# AE302F80F5582LE_CM55_HP_View register map
Vendor: Alif Semiconductor; Series: E3; File version: 1.0
CPU: CM55 r1p0, selectable endian, MPU, FPU, double-precision FPU, DSP, VTOR, 8 interrupt priority bits, 1 SAU regions
Registers are 32-bit, read-write, reset 0x0 unless marked. A register's access mark holds for its fields unless they carry their own. Offsets are from the block's base; [hi:lo] are bit positions; {n}, {i} and the like mark numbered series.

## CANFD0_CNT
Base 0x49037000
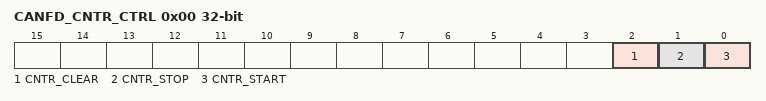
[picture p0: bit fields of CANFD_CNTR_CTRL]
0x00 CANFD_CNTR_CTRL wo — CANFD Counter Control Register
  [2] CNTR_CLEAR — Clear the CANFD counter.
  [1] CNTR_STOP — Stop the CANFD counter.
  [0] CNTR_START — Start the CANFD counter.
0x04 CANFD_CNTR_LOW — CANFD Counter Low Register
  [31:0] CNTR_LO — CANFD counter bits [31:0].
0x08 CANFD_CNTR_HIGH — CANFD Counter High Register
  [31:0] CNTR_HI — CANFD counter bits [63:32].

## AES0
Base 0x83001000
Same registers: AES1 0x83003000
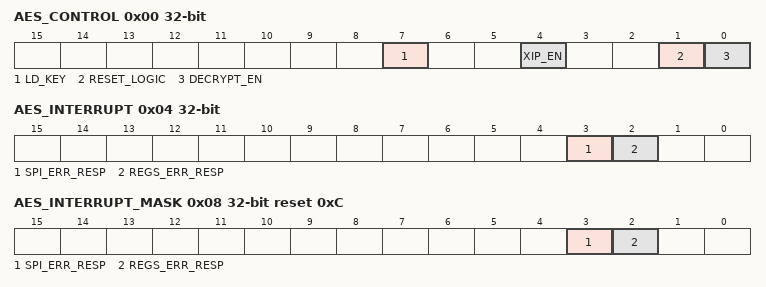
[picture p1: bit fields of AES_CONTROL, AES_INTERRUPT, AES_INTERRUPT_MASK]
0x00 AES_CONTROL
  [7] LD_KEY — Write 1 once the new key has been written by the Secure Enclave, so the key can be pre-processed by the AES engine. Read returns 0x0.
  [4] XIP_EN — When this bit is set, the OSPI can be used in XIP mode directly, with or without intervention from the decryption logic.
  [1] RESET_LOGIC — Reset the AES engine.
  [0] DECRYPT_EN — Decryption Enabled When set, this bit causes host read accesses to use the decryption logic rather than go directly to the OSPI module. Note that the OSPI module must be programmed to work in XIP mode prior to setting this bit.
0x04 AES_INTERRUPT — AES Interrupt Control Register
  [3] SPI_ERR_RESP — SPI Error Response interrupt enabling. Set when an error response is received from the OSPI through the AHB bus. Write 1 to clear bit.
    0=SPI Error Response interrupt is disabled; 1=SPI Error Response interrupt is enabled
  [2] REGS_ERR_RESP — Register Error Response interrupt enabling. Set when there is an access to an invalid AES register. Write 1 to clear bit.
    0=Register Error Response interrupt is disabled; 1=Register Error Response interrupt is enabled
0x08 AES_INTERRUPT_MASK reset 0xC
  [3] SPI_ERR_RESP — Mask for the SPI Error Response interrupt.
    0=SPI Error Response interrupt is not masked; 1=SPI Error Response interrupt is masked
  [2] REGS_ERR_RESP — Mask for the Register Error Response interrupt.
    0=Register Error Response interrupt is not masked; 1=Register Error Response interrupt is masked
0x20 AES_RXDS_DELAY — OSPI RXDS Delay Register
  [4:0] RXDS_DELAY — A delay added to the OSPI read data strobe (RXDS) input line in 0.5-ns steps. The maximum allowed value to program is 16. Note: The delay should be set to overcome the internal delay of OSPI input data lines (RXD) compared to the RXDS line. The objective is to ensure that the RXDS line is delayed by 1/4 OSPI clock cycle with respect to the leading edge of the valid RXD data lines. Equation to determine RXDS delay value: RXDS delay (ns) = RXD_delay (ns) + 0.25 x 1/FOSPI_SCLK For example, for internal RXD delay of 1.2 ns and 100 MHz OSPI clock, the RXDS delay = 1.2 ns + 0.25 x 1/100 MHz = 1.2 ns + 2.5 ns = 3.7 ns. The RXDS_DELAY code should be programmed to 0x8. This value may need to be calibrated for each specific application and may also depend on the pin multiplexing options selected for the OSPI data bus signals. For information on OSPI timing data, refer to Section OSPI Timing Characteristics of the device series-specific Datasheet.
    0=No delay; 1=0.5 ns delay; 2=2 x 0.5 ns delay; 15=15 x 0.5 ns delay; 16=16 x 0.5 ns delay

## M55HP_NVIC_S
Base 0xE000E100
Same registers: M55HP_NVIC_NS 0xE002E100
{0x0+4i} NVIC_ISER[{i}] (i=0..14) — Interrupt Set-Enable Register (n)
  [31:0] SETENA — Allows to enable an interrupt or read the status. For each bit: Read 0x0: Interrupt is disabled Read 0x1: Interrupt is enabled Write 0x0: No effect Write 0x1: Enable interrupt
{0x80+4i} NVIC_ICER[{i}] (i=0..14) — Interrupt Clear-Enable Register (n)
  [31:0] CLRENA — Allows to disable an interrupt or read the status. For each bit: Read 0x0: Interrupt is disabled Read 0x1: Interrupt is enabled Write 0x0: No effect Write 0x1: Disable interrupt
{0x100+4i} NVIC_ISPR[{i}] (i=0..14) — Interrupt Set-Pending Register (n)
  [31:0] SETPEND — Allows to set an interrupt to pending state or read the status. For each bit: Read 0x0: Interrupt is not pending Read 0x1: Interrupt is pending Write 0x0: No effect Write 0x1: Set interrupt to pending state
{0x180+4i} NVIC_ICPR[{i}] (i=0..14) — Interrupt Clear-Pending Register (n)
  [31:0] CLRPEND — Allows to clear an interrupt to not pending state or read the status. For each bit: Read 0x0: Interrupt is not pending Read 0x1: Interrupt is pending Write 0x0: No effect Write 0x1: Clear pending state of interrupt
{0x200+4i} NVIC_IABR[{i}] (i=0..14) ro — Interrupt Active Bit Register (n)
  [31:0] ACTIVE — Indicates the active state of an interrupt. For each bit:
    0=Interrupt is not active; 1=Interrupt is active
{0x280+4i} NVIC_ITNS[{i}] (i=0..14) — Interrupt Target Non-Secure Register (n)
  [31:0] ITNS — Determines whether an interrupt targets non-secure or secure state. For each bit:
    0=Interrupt targets secure state; 1=Interrupt targets non-secure state
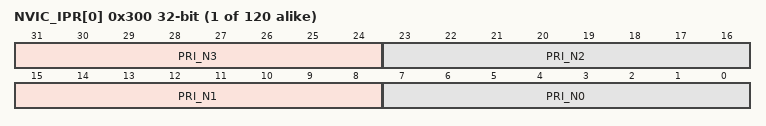
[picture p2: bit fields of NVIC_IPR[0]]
{0x300+4i} NVIC_IPR[{i}] (i=0..119) — Interrupt Priority Register (n)
  [31:24] PRI_N3 — Allows to set or read the priority level for interrupt 3
  [23:16] PRI_N2 — Allows to set or read the priority level for interrupt 2
  [15:8] PRI_N1 — Allows to set or read the priority level for interrupt 1
  [7:0] PRI_N0 — Allows to set or read the priority level for interrupt 0
    0=Priority level is 0 (highest); 1=Priority level is 1; 255=Priority level is 255 (lowest)
